VERSION "created by canmatrix"

NS_ :

BS_:

BU_: VCU GW

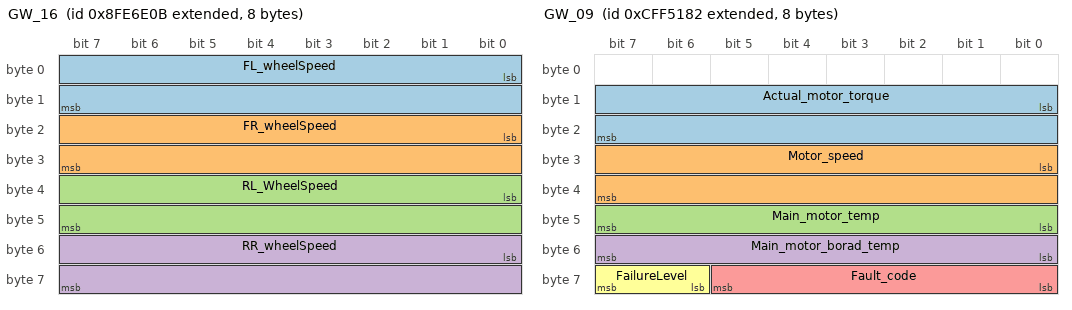
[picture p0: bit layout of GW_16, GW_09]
BO_ 2298375691 GW_16: 8 GW
 SG_ FL_wheelSpeed : 0|16@1+ (0.00390625,0) [0|65535] "-"  VCU
 SG_ FR_wheelSpeed : 16|16@1+ (0.00390625,0) [0|65535] "-"  VCU
 SG_ RL_WheelSpeed : 32|16@1+ (0.00390625,0) [0|65535] "-"  VCU
 SG_ RR_wheelSpeed : 48|16@1+ (0.00390625,0) [0|65535] "-"  VCU

BO_ 2365526778 GW_25: 8 GW
 SG_ Wheel_steering_Angle : 8|16@1+ (1,0) [0|65535] ""  VCU

BO_ 2365531949 EPS_01: 8 VCU
 SG_ EPSSteerAngReq : 0|16@1+ (0.1,-40) [0|65535] "deg"  GW
 SG_ EPSCtrlReq : 16|2@1+ (1,0) [0|3] ""  GW

BO_ 2365542786 GW_09: 8 GW
 SG_ Actual_motor_torque : 8|16@1+ (1,0) [0|65535] "Nm"  VCU
 SG_ Motor_speed : 24|16@1+ (0.25,0) [0|65535] "rmp"  VCU
 SG_ Main_motor_temp : 40|8@1+ (1,0) [0|255] ""  VCU
 SG_ Main_motor_borad_temp : 48|8@1+ (1,0) [0|255] ""  VCU
 SG_ Fault_code : 56|6@1+ (1,0) [0|63] ""  VCU
 SG_ FailureLevel : 62|2@1+ (1,0) [0|3] ""  VCU

BO_ 2365542787 GW_10: 8 GW
 SG_ Slave_motor_temp : 40|8@1+ (1,0) [0|255] ""  VCU
 SG_ Slave_motor_board_temp : 48|8@1+ (1,0) [0|255] ""  VCU

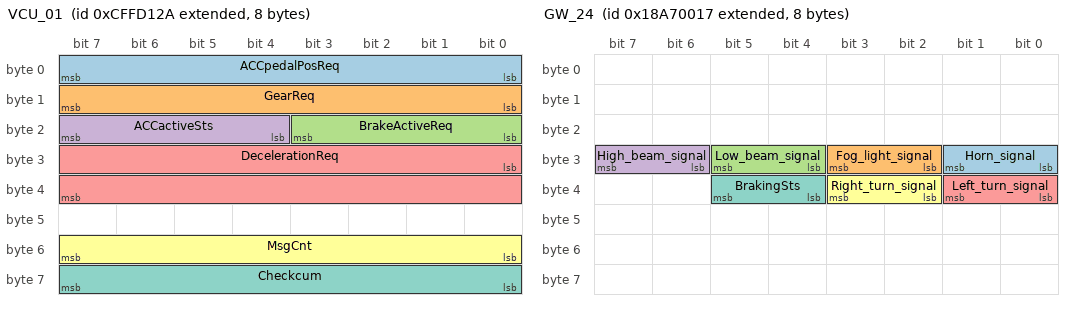
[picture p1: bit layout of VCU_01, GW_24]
BO_ 2365575466 VCU_01: 8 VCU
 SG_ ACCpedalPosReq : 0|8@1+ (0.4,0) [0|255] "%"  GW
 SG_ GearReq : 8|8@1+ (1,0) [0|255] ""  GW
 SG_ BrakeActiveReq : 16|4@1+ (1,0) [0|15] ""  GW
 SG_ ACCactiveSts : 20|4@1+ (1,0) [0|15] ""  GW
 SG_ DecelerationReq : 24|16@1+ (0.000488281,-15.687) [0|65535] "m/s2"  GW
 SG_ MsgCnt : 48|8@1+ (1,0) [0|255] ""  GW
 SG_ Checkcum : 56|8@1+ (1,0) [0|255] ""  GW

BO_ 2381448694 VCU_07: 8 VCU
 SG_ Vehicle_Power_supply_ctrl : 4|4@1+ (1,0) [0|15] ""  GW

BO_ 2561081367 GW_24: 8 GW
 SG_ Horn_signal : 24|2@1+ (1,0) [0|3] ""  VCU
 SG_ Fog_light_signal : 27|2@0+ (1,0) [0|3] ""  VCU
 SG_ Low_beam_signal : 28|2@1+ (1,0) [0|3] ""  VCU
 SG_ High_beam_signal : 30|2@1+ (1,0) [0|3] ""  VCU
 SG_ Left_turn_signal : 32|2@1+ (1,0) [0|3] ""  VCU
 SG_ Right_turn_signal : 34|2@1+ (1,0) [0|3] ""  VCU
 SG_ BrakingSts : 36|2@1+ (1,0) [0|3] ""  VCU

BO_ 2565867787 GW_17: 8 GW
 SG_ Longitudinal_acceleration : 56|8@1+ (0.1,-12.5) [0|255] "m/s2"  VCU

BO_ 2566769962 VCU_04: 8 VCU
 SG_ WiperControl : 4|4@1+ (1,0) [0|15] ""  GW
 SG_ WashControl : 45|3@1+ (1,0) [0|7] ""  GW

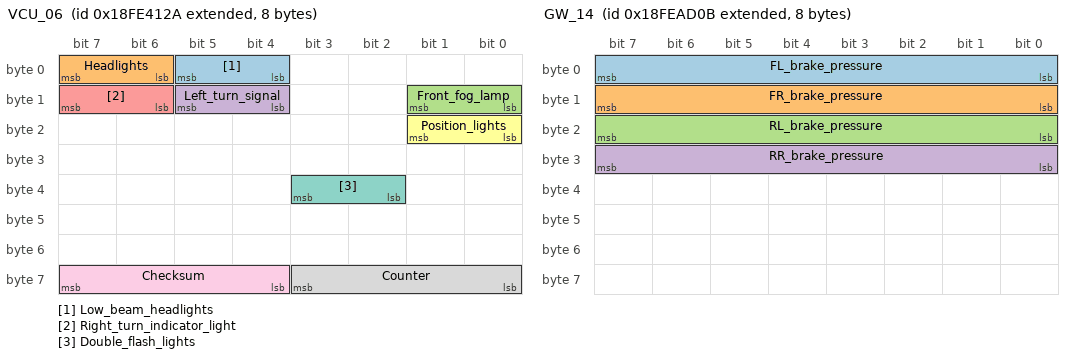
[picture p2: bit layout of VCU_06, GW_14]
BO_ 2566799658 VCU_06: 8 VCU
 SG_ Low_beam_headlights : 4|2@1+ (1,0) [0|3] ""  GW
 SG_ Headlights : 6|2@1+ (1,0) [0|3] ""  GW
 SG_ Front_fog_lamp : 8|2@1+ (1,0) [0|3] ""  GW
 SG_ Left_turn_signal : 12|2@1+ (1,0) [0|3] ""  GW
 SG_ Right_turn_indicator_light : 14|2@1+ (1,0) [0|3] ""  GW
 SG_ Position_lights : 16|2@1+ (1,0) [0|3] ""  GW
 SG_ Double_flash_lights : 34|2@1+ (1,0) [0|3] ""  GW
 SG_ Counter : 56|4@1+ (1,0) [0|15] ""  GW
 SG_ Checksum : 60|4@1+ (1,0) [0|15] ""  GW

BO_ 2566827275 GW_14: 8 GW
 SG_ FL_brake_pressure : 0|8@1+ (5,0) [0|255] "Kpa"  VCU
 SG_ FR_brake_pressure : 8|8@1+ (5,0) [0|255] "Kpa"  VCU
 SG_ RL_brake_pressure : 16|8@1+ (5,0) [0|255] "Kpa"  VCU
 SG_ RR_brake_pressure : 24|8@1+ (5,0) [0|255] "Kpa"  VCU

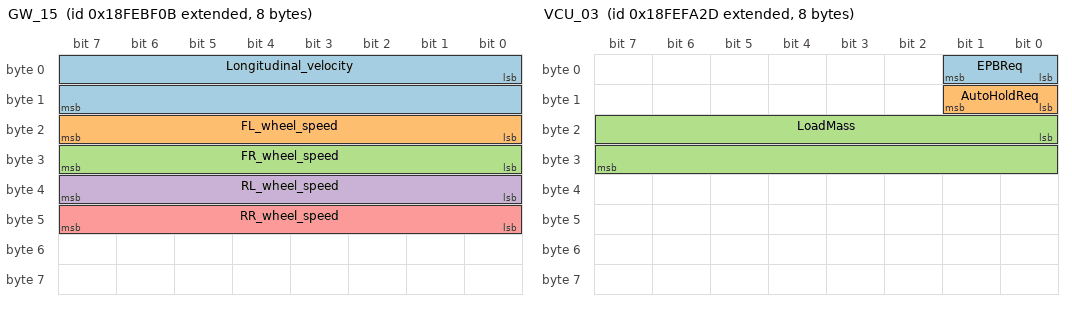
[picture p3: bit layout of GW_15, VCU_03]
BO_ 2566831883 GW_15: 8 GW
 SG_ Longitudinal_velocity : 0|16@1+ (0.00390625,0) [0|255.99609375] "km/h"  VCU
 SG_ FL_wheel_speed : 16|8@1+ (0.0625,-7.8125) [0|255] "km/h"  VCU
 SG_ FR_wheel_speed : 24|8@1+ (0.0625,-7.8125) [0|255] "km/h"  VCU
 SG_ RL_wheel_speed : 32|8@1+ (0.0625,-7.8125) [0|255] "km/h"  VCU
 SG_ RR_wheel_speed : 40|8@1+ (0.0625,-7.8125) [0|255] "km/h"  VCU

BO_ 2566832407 GW_20: 8 GW
 SG_ Total_mileage_info : 0|32@1+ (5,0) [0|4294967295] "m"  VCU

BO_ 2566847021 VCU_03: 8 VCU
 SG_ EPBReq : 0|2@1+ (1,0) [0|3] ""  GW
 SG_ AutoHoldReq : 8|2@1+ (1,0) [0|3] ""  GW
 SG_ LoadMass : 16|16@1+ (0.01,0) [0|65535] "t"  GW

BO_ 2566850596 GW_04: 8 GW
 SG_ State_of_vehicle : 37|3@1+ (1,0) [0|7] ""  VCU

BO_ 2566852388 GW_07: 8 GW
 SG_ START_ignition : 29|1@1+ (1,0) [0|1] ""  VCU

BO_ 2566853668 GW_08: 8 GW
 SG_ Electronic_parking_state : 40|3@1+ (1,0) [0|7] ""  VCU

BO_ 2566854436 GW_06: 8 GW
 SG_ AutoHold_status_indicator : 20|2@1+ (1,0) [0|3] ""  VCU

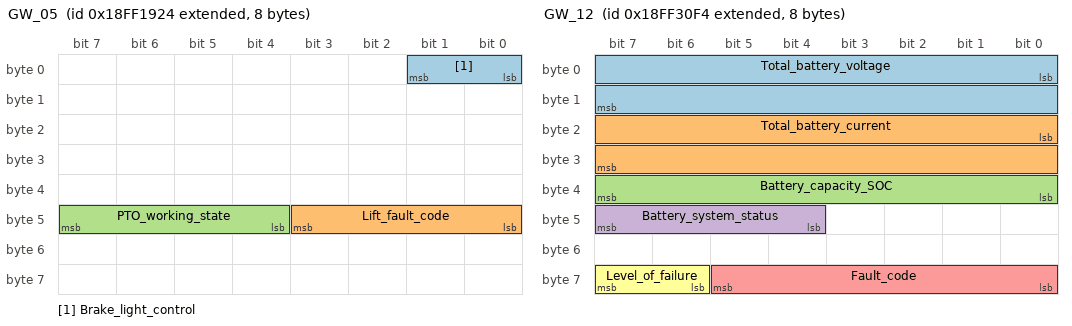
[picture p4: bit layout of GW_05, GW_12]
BO_ 2566854948 GW_05: 8 GW
 SG_ Brake_light_control : 0|2@1+ (1,0) [0|3] ""  VCU
 SG_ Lift_fault_code : 40|4@1+ (1,0) [0|15] ""  VCU
 SG_ PTO_working_state : 44|4@1+ (1,0) [0|15] ""  VCU

BO_ 2566860275 GW_11: 8 GW
 SG_ DCDC_controller : 56|2@1+ (1,0) [0|3] ""  VCU

BO_ 2566861044 GW_12: 8 GW
 SG_ Total_battery_voltage : 0|16@1+ (0.1,0) [0|65535] "V"  VCU
 SG_ Total_battery_current : 16|16@1+ (0.05,0) [0|65535] "A"  VCU
 SG_ Battery_capacity_SOC : 32|8@1+ (0.4,0) [0|255] "%"  VCU
 SG_ Battery_system_status : 44|4@1+ (1,0) [0|15] ""  VCU
 SG_ Fault_code : 56|6@1+ (1,0) [0|63] ""  VCU
 SG_ Level_of_failure : 62|2@1+ (1,0) [0|3] ""  VCU

BO_ 2566861556 GW_13: 8 GW
 SG_ Single_cell_MaxTemp : 0|8@1+ (1,0) [0|255] ""  VCU
 SG_ Single_cell_Mintemp : 24|8@1+ (1,0) [0|255] ""  VCU

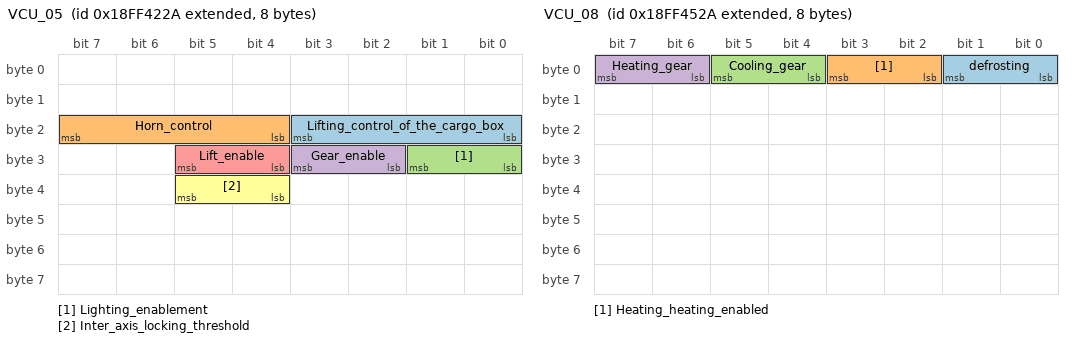
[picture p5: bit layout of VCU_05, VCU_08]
BO_ 2566865450 VCU_05: 8 VCU
 SG_ Lifting_control_of_the_cargo_box : 16|4@1+ (1,0) [0|15] ""  GW
 SG_ Horn_control : 20|4@1+ (1,0) [0|15] ""  GW
 SG_ Lighting_enablement : 24|2@1+ (1,0) [0|3] ""  GW
 SG_ Gear_enable : 26|2@1+ (1,0) [0|3] ""  GW
 SG_ Lift_enable : 28|2@1+ (1,0) [0|3] ""  GW
 SG_ Inter_axis_locking_threshold : 36|2@1+ (1,0) [0|3] ""  GW

BO_ 2566866218 VCU_08: 8 VCU
 SG_ defrosting : 0|2@1+ (1,0) [0|3] ""  GW
 SG_ Heating_heating_enabled : 2|2@1+ (1,0) [0|3] ""  GW
 SG_ Cooling_gear : 4|2@1+ (1,0) [0|3] ""  GW
 SG_ Heating_gear : 6|2@1+ (1,0) [0|3] ""  GW

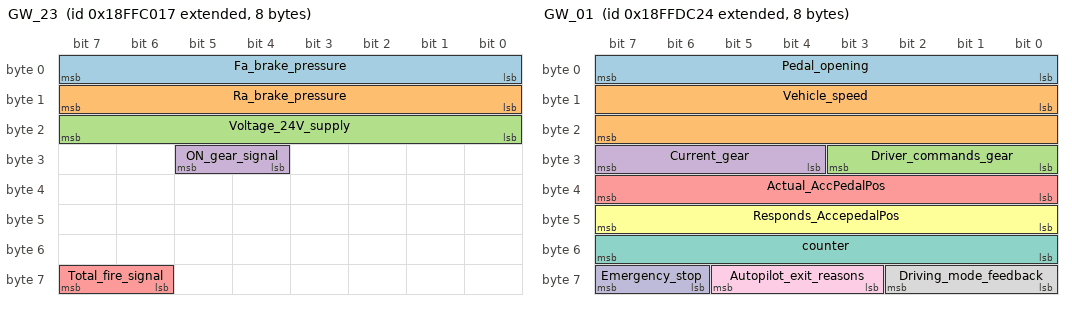
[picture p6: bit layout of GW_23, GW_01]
BO_ 2566897687 GW_23: 8 GW
 SG_ Fa_brake_pressure : 0|8@1+ (4,0) [0|255] "Kpa"  VCU
 SG_ Ra_brake_pressure : 8|8@1+ (4,0) [0|255] "Kpa"  VCU
 SG_ Voltage_24V_supply : 16|8@1+ (0.5,0) [0|255] "V"  VCU
 SG_ ON_gear_signal : 28|2@1+ (1,0) [0|3] ""  VCU
 SG_ Total_fire_signal : 62|2@1+ (1,0) [0|3] ""  VCU

BO_ 2566900759 GW_19: 8 GW
 SG_ Feedback_slow_handle_gear : 56|3@1+ (1,0) [0|7] ""  VCU

BO_ 2566904362 VCU_02: 8 VCU
 SG_ ADControlMode : 0|3@1+ (1,0) [0|7] ""  GW
 SG_ SlowSpdLeverGearControl : 40|3@1+ (1,0) [0|7] ""  GW

BO_ 2566904868 GW_01: 8 GW
 SG_ Pedal_opening : 0|8@1+ (0.4,0) [0|255] "-"  VCU
 SG_ Vehicle_speed : 8|16@1+ (0.00390625,0) [0|65535] "-"  VCU
 SG_ Driver_commands_gear : 24|4@1+ (1,0) [0|15] ""  VCU
 SG_ Current_gear : 28|4@1+ (1,0) [0|15] ""  VCU
 SG_ Actual_AccPedalPos : 32|8@1+ (0.4,0) [0|255] "-"  VCU
 SG_ Responds_AccepedalPos : 40|8@1+ (0.4,0) [0|255] "-"  VCU
 SG_ counter : 48|8@1+ (1,0) [0|255] ""  VCU
 SG_ Driving_mode_feedback : 56|3@1+ (1,0) [0|7] ""  VCU
 SG_ Autopilot_exit_reasons : 59|3@1+ (1,0) [0|7] ""  VCU
 SG_ Emergency_stop : 62|2@1+ (1,0) [0|3] ""  VCU

BO_ 2566906135 GW_22: 8 GW
 SG_ Small_light_status : 0|2@1+ (1,0) [0|3] ""  VCU

BO_ 2583647255 GW_21: 8 GW
 SG_ State_of_lift : 6|1@1+ (1,0) [0|1] ""  VCU
 SG_ Interaxis_lock_threshold_state : 12|2@1+ (1,0) [0|3] ""  VCU

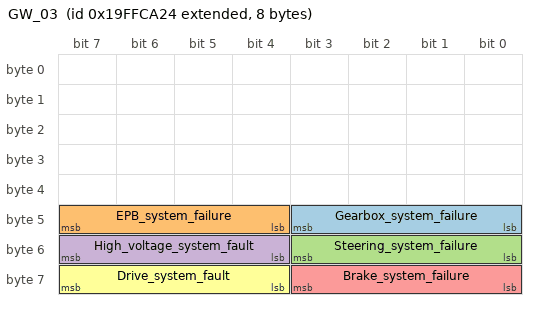
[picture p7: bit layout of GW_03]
BO_ 2583677476 GW_03: 8 GW
 SG_ Gearbox_system_failure : 40|4@1+ (1,0) [0|15] ""  VCU
 SG_ EPB_system_failure : 44|4@1+ (1,0) [0|15] ""  VCU
 SG_ Steering_system_failure : 48|4@1+ (1,0) [0|15] ""  VCU
 SG_ High_voltage_system_fault : 52|4@1+ (1,0) [0|15] ""  VCU
 SG_ Brake_system_failure : 56|4@1+ (1,0) [0|15] ""  VCU
 SG_ Drive_system_fault : 60|4@1+ (1,0) [0|15] ""  VCU

BO_ 2583677732 GW_02: 8 GW
 SG_ Average_powerConsumption : 0|11@1+ (0.1,-80) [0|2047] "kwh/km"  VCU
 SG_ Instantaneous_powerConsumption : 16|11@1+ (0.1,-100) [0|2047] "kwh/km"  VCU

BO_ 2583687427 GW_18: 8 GW
 SG_ Fault_code : 56|6@1+ (1,0) [0|63] ""  VCU
 SG_ Level_of_failure : 62|2@1+ (1,0) [0|3] ""  VCU

CM_ SG_ 2298375691 FL_wheelSpeed "ֵ0~0xFAFF";
CM_ SG_ 2298375691 FR_wheelSpeed "ֵ0~0xFAFF";
CM_ SG_ 2298375691 RL_WheelSpeed "ֵ0~0xFAFF";
CM_ SG_ 2298375691 RR_wheelSpeed "ֵ0~0xFAFF";
CM_ SG_ 2365526778 Wheel_steering_Angle "ֵ100-4900";
CM_ SG_ 2565867787 Longitudinal_acceleration "ֵ-12.5~12.5m/s2";
CM_ SG_ 2566832407 Total_mileage_info "ֵ0-0xFFFF";
CM_ SG_ 2566854948 PTO_working_state "PTO״̬";
CM_ SG_ 2566861044 Fault_code "0x00";
CM_ SG_ 2566897687 Fa_brake_pressure "ֵ0-1000kpa";
CM_ SG_ 2566897687 Ra_brake_pressure "ֵ0-1000KPA";
CM_ SG_ 2566897687 Voltage_24V_supply "ֵ0to32V";
CM_ SG_ 2583687427 Fault_code "0";
BA_DEF_ BO_  "GenMsgCycleTime" INT 0 65535;
BA_DEF_ BO_  "GenMsgSendType" ENUM  "Cyclic";
BA_DEF_DEF_  "GenMsgCycleTime" 0;
BA_DEF_DEF_  "GenMsgSendType" "";
BA_ "GenMsgSendType" BO_ 2298375691 0;
BA_ "GenMsgCycleTime" BO_ 2298375691 100;
BA_ "GenMsgSendType" BO_ 2365526778 0;
BA_ "GenMsgCycleTime" BO_ 2365526778 100;
BA_ "GenMsgSendType" BO_ 2365531949 0;
BA_ "GenMsgCycleTime" BO_ 2365531949 100;
BA_ "GenMsgSendType" BO_ 2365542786 0;
BA_ "GenMsgCycleTime" BO_ 2365542786 100;
BA_ "GenMsgSendType" BO_ 2365542787 0;
BA_ "GenMsgCycleTime" BO_ 2365542787 100;
BA_ "GenMsgSendType" BO_ 2365575466 0;
BA_ "GenMsgCycleTime" BO_ 2365575466 100;
BA_ "GenMsgSendType" BO_ 2381448694 0;
BA_ "GenMsgCycleTime" BO_ 2381448694 100;
BA_ "GenMsgSendType" BO_ 2561081367 0;
BA_ "GenMsgCycleTime" BO_ 2561081367 100;
BA_ "GenMsgSendType" BO_ 2565867787 0;
BA_ "GenMsgCycleTime" BO_ 2565867787 100;
BA_ "GenMsgSendType" BO_ 2566769962 0;
BA_ "GenMsgCycleTime" BO_ 2566769962 100;
BA_ "GenMsgSendType" BO_ 2566799658 0;
BA_ "GenMsgCycleTime" BO_ 2566799658 100;
BA_ "GenMsgSendType" BO_ 2566827275 0;
BA_ "GenMsgCycleTime" BO_ 2566827275 100;
BA_ "GenMsgSendType" BO_ 2566831883 0;
BA_ "GenMsgCycleTime" BO_ 2566831883 100;
BA_ "GenMsgSendType" BO_ 2566832407 0;
BA_ "GenMsgCycleTime" BO_ 2566832407 1000;
BA_ "GenMsgSendType" BO_ 2566847021 0;
BA_ "GenMsgCycleTime" BO_ 2566847021 100;
BA_ "GenMsgSendType" BO_ 2566850596 0;
BA_ "GenMsgCycleTime" BO_ 2566850596 100;
BA_ "GenMsgSendType" BO_ 2566852388 0;
BA_ "GenMsgCycleTime" BO_ 2566852388 100;
BA_ "GenMsgSendType" BO_ 2566853668 0;
BA_ "GenMsgCycleTime" BO_ 2566853668 100;
BA_ "GenMsgSendType" BO_ 2566854436 0;
BA_ "GenMsgCycleTime" BO_ 2566854436 100;
BA_ "GenMsgSendType" BO_ 2566854948 0;
BA_ "GenMsgCycleTime" BO_ 2566854948 100;
BA_ "GenMsgSendType" BO_ 2566860275 0;
BA_ "GenMsgCycleTime" BO_ 2566860275 100;
BA_ "GenMsgSendType" BO_ 2566861044 0;
BA_ "GenMsgCycleTime" BO_ 2566861044 100;
BA_ "GenMsgSendType" BO_ 2566861556 0;
BA_ "GenMsgCycleTime" BO_ 2566861556 100;
BA_ "GenMsgSendType" BO_ 2566865450 0;
BA_ "GenMsgCycleTime" BO_ 2566865450 100;
BA_ "GenMsgSendType" BO_ 2566866218 0;
BA_ "GenMsgCycleTime" BO_ 2566866218 100;
BA_ "GenMsgSendType" BO_ 2566897687 0;
BA_ "GenMsgCycleTime" BO_ 2566897687 100;
BA_ "GenMsgSendType" BO_ 2566900759 0;
BA_ "GenMsgCycleTime" BO_ 2566900759 100;
BA_ "GenMsgSendType" BO_ 2566904362 0;
BA_ "GenMsgCycleTime" BO_ 2566904362 100;
BA_ "GenMsgSendType" BO_ 2566904868 0;
BA_ "GenMsgCycleTime" BO_ 2566904868 100;
BA_ "GenMsgSendType" BO_ 2566906135 0;
BA_ "GenMsgCycleTime" BO_ 2566906135 100;
BA_ "GenMsgSendType" BO_ 2583647255 0;
BA_ "GenMsgCycleTime" BO_ 2583647255 100;
BA_ "GenMsgSendType" BO_ 2583677476 0;
BA_ "GenMsgCycleTime" BO_ 2583677476 100;
BA_ "GenMsgSendType" BO_ 2583677732 0;
BA_ "GenMsgCycleTime" BO_ 2583677732 100;
BA_ "GenMsgSendType" BO_ 2583687427 0;
BA_ "GenMsgCycleTime" BO_ 2583687427 100;
VAL_ 2365531949 EPSCtrlReq 0 "" 1 "" ;
VAL_ 2365542786 Fault_code 0 "" ;
VAL_ 2365542786 FailureLevel 0 "" 1 "һ" 2 "" 3 "" ;
VAL_ 2365575466 GearReq 0 "N" 32 "D" 64 "R" 96 "L" ;
VAL_ 2365575466 BrakeActiveReq 0 "" 1 "" ;
VAL_ 2365575466 ACCactiveSts 0 "" 1 "" ;
VAL_ 2381448694 Vehicle_Power_supply_ctrl 0 "" 2 "" 3 "Reday" ;
VAL_ 2561081367 Horn_signal 0 "OFF" 1 "ON" ;
VAL_ 2561081367 Fog_light_signal 0 "OFF" 1 "ON" ;
VAL_ 2561081367 Low_beam_signal 0 "OFF" 1 "ON" ;
VAL_ 2561081367 High_beam_signal 0 "OFF" 1 "ON" ;
VAL_ 2561081367 Left_turn_signal 0 "OFF" 1 "ON" ;
VAL_ 2561081367 Right_turn_signal 0 "OFF" 1 "ON" ;
VAL_ 2561081367 BrakingSts 0 "״̬OFF" 1 "״̬ON" ;
VAL_ 2566769962 WiperControl 0 "";
VAL_ 2566769962 WashControl 0 "of" 1 "O" ;
VAL_ 2566799658 Low_beam_headlights 0 "" 1 "" ;
VAL_ 2566799658 Headlights 0 "" 1 "" ;
VAL_ 2566799658 Front_fog_lamp 0 "" 1 "" ;
VAL_ 2566799658 Left_turn_signal 0 "" 1 "" ;
VAL_ 2566799658 Right_turn_indicator_light 0 "" 1 "" ;
VAL_ 2566799658 Position_lights 0 "" 1 "" ;
VAL_ 2566799658 Double_flash_lights 0 "" 1 "" ;
VAL_ 2566847021 EPBReq 0 "ֵ" 1 "EPB" 2 "EPB" ;
VAL_ 2566847021 AutoHoldReq 0 "ֵ" 1 "Auto_Hold" 2 "Auto_Hold" ;
VAL_ 2566850596 State_of_vehicle 1 "STOP" 2 "READY" 3 "GO!" ;
VAL_ 2566852388 START_ignition 0 "" 1 "" ;
VAL_ 2566853668 Electronic_parking_state 0 "" 1 "" ;
VAL_ 2566854436 AutoHold_status_indicator 0 "" 1 "" ;
VAL_ 2566854948 Brake_light_control 0 "" 1 "" ;
VAL_ 2566854948 Lift_fault_code 0 "" 1 "" ;
VAL_ 2566854948 PTO_working_state 0 "" 1 "" 2 "" 3 "" 4 "";
VAL_ 2566860275 DCDC_controller 0 "" 1 "" 2 "" 3 "" ;
VAL_ 2566861044 Battery_system_status 0 "" 2 "" 6 "DCDC" 12 "" 14 "" ;
VAL_ 2566861044 Level_of_failure 0 "" 1 "" 2 "" 3 "" ;
VAL_ 2566865450 Lifting_control_of_the_cargo_box 0 "" 1 "" 2 "" 3 "" ;
VAL_ 2566865450 Horn_control 0 "" 1 "" ;
VAL_ 2566865450 Lighting_enablement 0 "" 1 "" ;
VAL_ 2566865450 Gear_enable 0 "" 1 "" ;
VAL_ 2566865450 Lift_enable 0 "" 1 "" ;
VAL_ 2566865450 Inter_axis_locking_threshold 0 "" 1 "" ;
VAL_ 2566866218 defrosting 0 "" 1 "" ;
VAL_ 2566866218 Heating_heating_enabled 0 "" 2 "" ;
VAL_ 2566866218 Cooling_gear 0 "" 2 "" 3 "" ;
VAL_ 2566866218 Heating_gear 0 "" ;
VAL_ 2566897687 ON_gear_signal 0 "" 1 "NO" ;
VAL_ 2566897687 Total_fire_signal 0 "" 1 "ܻ" ;
VAL_ 2566900759 Feedback_slow_handle_gear 0 "" 1 "" 2 "" 3 "" ;
VAL_ 2566904362 ADControlMode 0 " " 1 "" 3 "" ;
VAL_ 2566904362 SlowSpdLeverGearControl 0 " 1 " 1 " 16 " 2 " 17 " 3 " 256 " ;
VAL_ 2566904868 Driver_commands_gear 0 "N" 1 "D" 2 "R" 3 "L" ;
VAL_ 2566904868 Current_gear 0 "N" 1 "D" 2 "R" 3 "L" ;
VAL_ 2566904868 Driving_mode_feedback 0 "" 1 "" 2 "" ;
VAL_ 2566904868 Autopilot_exit_reasons 0 "" 1 "" 2 "" 3 "" 4 "" 5 "" 6 "" 7 "" ;
VAL_ 2566904868 Emergency_stop 0 "" 1 "" ;
VAL_ 2566906135 Small_light_status 0 "" 1 "" ;
VAL_ 2583647255 State_of_lift 0 "" 1 "" ;
VAL_ 2583647255 Interaxis_lock_threshold_state 0 "" 1 "" ;
VAL_ 2583677476 Gearbox_system_failure 0 "" 1 "" 2 "" ;
VAL_ 2583677476 EPB_system_failure 0 "" 1 "" 2 "" ;
VAL_ 2583677476 Steering_system_failure 0 "" 1 "" 2 "" ;
VAL_ 2583677476 High_voltage_system_fault 0 "" 1 "" ;
VAL_ 2583677476 Brake_system_failure 0 "" 1 "" 2 "" ;
VAL_ 2583677476 Drive_system_fault 0 "" 1 "" 2 "" 3 "";
VAL_ 2583687427 Fault_code 0 "" ;
VAL_ 2583687427 Level_of_failure 0 "" 1 "" 2 "" 3 "" ;
